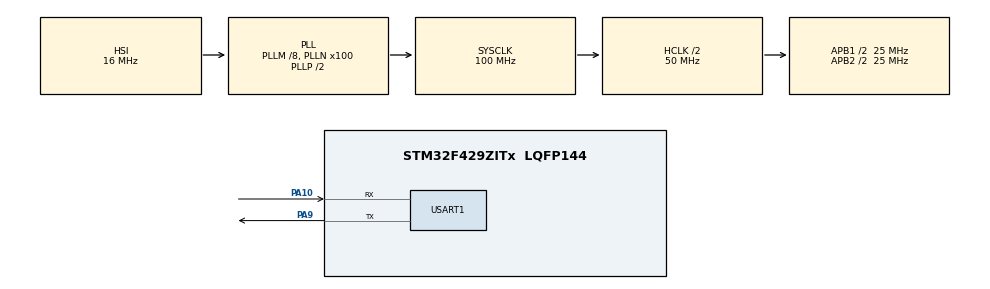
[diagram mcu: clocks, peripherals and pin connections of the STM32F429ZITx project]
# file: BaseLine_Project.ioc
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Mcu.Family=STM32F4
Mcu.Name=STM32F429ZITx
Mcu.Package=LQFP144
NVIC.PriorityGroup=NVIC_PRIORITYGROUP_4
NVIC.TIM1_UP_TIM10_IRQn=true\:14\:0\:true\:false\:true\:true\:true\:true
NVIC.USART1_IRQn=true\:13\:0\:true\:false\:true\:true\:true\:true
PA10.Mode=Asynchronous
PA10.Signal=USART1_RX
PA9.Mode=Asynchronous
PA9.Signal=USART1_TX
ProjectManager.HeapSize=0x200
ProjectManager.StackSize=0x400
ProjectManager.TargetToolchain=CMake
RCC.48MHZClocksFreq_Value=50000000
RCC.AHBCLKDivider=RCC_SYSCLK_DIV2
RCC.AHBFreq_Value=50000000
RCC.APB1CLKDivider=RCC_HCLK_DIV2
RCC.APB1Freq_Value=25000000
RCC.APB1TimFreq_Value=50000000
RCC.APB2CLKDivider=RCC_HCLK_DIV2
RCC.APB2Freq_Value=25000000
RCC.APB2TimFreq_Value=50000000
RCC.CortexFreq_Value=50000000
RCC.HCLKFreq_Value=50000000
RCC.HSE_VALUE=25000000
RCC.HSI_VALUE=16000000
RCC.LSE_VALUE=32768
RCC.PLLM=8
RCC.PLLN=100
RCC.SYSCLKFreq_VALUE=100000000
RCC.SYSCLKSource=RCC_SYSCLKSOURCE_PLLCLK
RCC.VCOOutputFreq_Value=200000000
USART1.VirtualMode=VM_ASYNC
VP_TIM1_VS_ClockSourceINT.Mode=Internal
board=custom

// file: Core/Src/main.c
/* USER CODE BEGIN Header */
/**
  ******************************************************************************
  * @file           : main.c
  * @brief          : Main program body
  ******************************************************************************
  * @attention
  *
  * Copyright (c) 2025 STMicroelectronics.
  * All rights reserved.
  *
  * This software is licensed under terms that can be found in the LICENSE file
  * in the root directory of this software component.
  * If no LICENSE file comes with this software, it is provided AS-IS.
  *
  ******************************************************************************
  */
/* USER CODE END Header */
#include "main.h"
#include "log_uart.h"

/* USER CODE BEGIN PD */
#define RXBUFFERSIZE 128
/* USER CODE END PD */

/* USER CODE BEGIN PV */
volatile uint8_t PeriodicScheduler;
uint8_t rxBuffer[RXBUFFERSIZE];
/* USER CODE END PV */

void SystemClock_Config(void);

int no_main(void)
{

  /* MCU Configuration--------------------------------------------------------*/

  /* Reset of all peripherals, Initializes the Flash interface and the Systick. */
  HAL_Init();

  /* Configure the system clock */
  SystemClock_Config();

  /* Initialize all configured peripherals */
  MX_GPIO_Init();
  MX_TIM1_Init();
  MX_USART1_UART_Init();
  LOG_UART_Init();
  /* USER CODE BEGIN 2 */
  HAL_TIM_Base_Start_IT(&htim1); // Start Timer 1 in interrupt mode
  HAL_UART_Receive_IT(&huart1, (uint8_t *)rxBuffer, RXBUFFERSIZE); // Start UART reception in interrupt mode
  printf("[Logger Test]\r\n");
  /* USER CODE END 2 */

  /* Infinite loop */
  /* USER CODE BEGIN WHILE */
  static uint32_t loop_counter = 0;
  static uint8_t toggle = 0;

  while (1)
  {
    /* USER CODE END WHILE */

    /* USER CODE BEGIN 3 */
    if(PeriodicScheduler == 1U)
    {
      PeriodicScheduler = 0U;

      // Increment loop counter for debugging
      loop_counter++;

      // Your periodic task code here
      printf("[%lu] Hello from UART! Toggle: %d\r\n", loop_counter, toggle);

      if(loop_counter >= 25)
      {
        switch(toggle)
        {
          case 0:
            HAL_GPIO_WritePin(GPIOG, GPIO_PIN_2, GPIO_PIN_SET); // Toggle the LED on Pin PG14
            printf("[%lu] LED PG2 toggled, reset counter\r\n", loop_counter);
            toggle = 1U;
            break;
          case 1:
            HAL_GPIO_WritePin(GPIOG, GPIO_PIN_13, GPIO_PIN_SET); // Toggle the LED on Pin PG13
            printf("[%lu] LED PG13 toggled, reset counter\r\n", loop_counter);
            toggle = 2U;
            break;
          case 2:
            HAL_GPIO_WritePin(GPIOD, GPIO_PIN_11, GPIO_PIN_SET); // Toggle the LED on Pin PD13
            printf("[%lu] LED PD11 toggled, reset counter\r\n", loop_counter);
            toggle = 3U;
            break;
          default:
            HAL_GPIO_WritePin(GPIOG, GPIO_PIN_2, GPIO_PIN_RESET);
            HAL_GPIO_WritePin(GPIOG, GPIO_PIN_13, GPIO_PIN_RESET);
            HAL_GPIO_WritePin(GPIOD, GPIO_PIN_11, GPIO_PIN_RESET);
            toggle = 0U;
        }
        loop_counter = 0U;
     }
    }
  }

    // Small delay to prevent overwhelming the system
    HAL_Delay(1);
  }
  /* USER CODE END 3 */

void SystemClock_Config(void)
{
  RCC_OscInitTypeDef RCC_OscInitStruct = {0};
  RCC_ClkInitTypeDef RCC_ClkInitStruct = {0};

  /** Configure the main internal regulator output voltage
  */
  __HAL_RCC_PWR_CLK_ENABLE();
  __HAL_PWR_VOLTAGESCALING_CONFIG(PWR_REGULATOR_VOLTAGE_SCALE3);

  /** Initializes the RCC Oscillators according to the specified parameters
  * in the RCC_OscInitTypeDef structure.
  */
  RCC_OscInitStruct.OscillatorType = RCC_OSCILLATORTYPE_HSI;
  RCC_OscInitStruct.HSIState = RCC_HSI_ON;
  RCC_OscInitStruct.HSICalibrationValue = RCC_HSICALIBRATION_DEFAULT;
  RCC_OscInitStruct.PLL.PLLState = RCC_PLL_ON;
  RCC_OscInitStruct.PLL.PLLSource = RCC_PLLSOURCE_HSI;
  RCC_OscInitStruct.PLL.PLLM = 8;
  RCC_OscInitStruct.PLL.PLLN = 100;
  RCC_OscInitStruct.PLL.PLLP = RCC_PLLP_DIV2;
  RCC_OscInitStruct.PLL.PLLQ = 4;
  if (HAL_RCC_OscConfig(&RCC_OscInitStruct) != HAL_OK)
  {
    Error_Handler();
  }

  /** Initializes the CPU, AHB and APB buses clocks
  */
  RCC_ClkInitStruct.ClockType = RCC_CLOCKTYPE_HCLK|RCC_CLOCKTYPE_SYSCLK
                              |RCC_CLOCKTYPE_PCLK1|RCC_CLOCKTYPE_PCLK2;
  RCC_ClkInitStruct.SYSCLKSource = RCC_SYSCLKSOURCE_PLLCLK;
  RCC_ClkInitStruct.AHBCLKDivider = RCC_SYSCLK_DIV2;
  RCC_ClkInitStruct.APB1CLKDivider = RCC_HCLK_DIV2;
  RCC_ClkInitStruct.APB2CLKDivider = RCC_HCLK_DIV2;

  if (HAL_RCC_ClockConfig(&RCC_ClkInitStruct, FLASH_LATENCY_1) != HAL_OK)
  {
    Error_Handler();
  }
}

void Error_Handler(void)
{
  __disable_irq();
  while (1)
  {
  }
}
